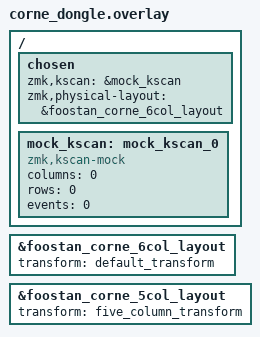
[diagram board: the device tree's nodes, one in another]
#include <dt-bindings/zmk/matrix_transform.h>

#include <layouts/foostan/corne/5column.dtsi>
#include <layouts/foostan/corne/6column.dtsi>

&foostan_corne_6col_layout {
    transform = <&default_transform>;
};

&foostan_corne_5col_layout {
    transform = <&five_column_transform>;
};

/ {
    chosen {
        zmk,kscan = &mock_kscan;
        zmk,physical-layout = &foostan_corne_6col_layout;

    };

    mock_kscan: mock_kscan_0 {
        compatible = "zmk,kscan-mock";
        columns = <0>;
        rows = <0>;
        events = <0>;
    };
};
